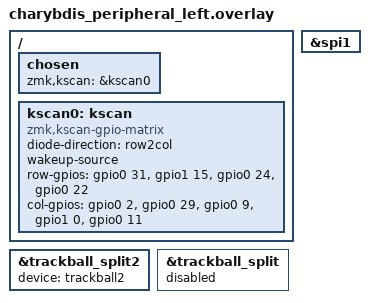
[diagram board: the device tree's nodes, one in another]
/*
 * Copyright (c) 2020 ZMK Contributors
 *
 * SPDX-License-Identifier: MIT
 */

#include "charybdis.dtsi"
#include "trackball.dtsi"
#include "split_input_common.dtsi"


/ {
    chosen {
        zmk,kscan = &kscan0;
    };
    
    kscan0: kscan {
        compatible = "zmk,kscan-gpio-matrix";
        diode-direction = "row2col";
        wakeup-source;

	row-gpios
        = <&gpio0 31 GPIO_ACTIVE_HIGH>
        , <&gpio1 15 GPIO_ACTIVE_HIGH>
        , <&gpio0 24 GPIO_ACTIVE_HIGH>
	    , <&gpio0 22 GPIO_ACTIVE_HIGH>
        ;
	col-gpios
		= <&gpio0 2 (GPIO_ACTIVE_HIGH | GPIO_PULL_DOWN)>
		, <&gpio0 29 (GPIO_ACTIVE_HIGH | GPIO_PULL_DOWN)>
		, <&gpio0 9 (GPIO_ACTIVE_HIGH | GPIO_PULL_DOWN)>
		, <&gpio1 0  (GPIO_ACTIVE_HIGH | GPIO_PULL_DOWN)>
		, <&gpio0 11 (GPIO_ACTIVE_HIGH | GPIO_PULL_DOWN)>
		;
	};
};

&spi1 {
    status = "okay";
};
&trackball_split2 {
	device = <&trackball2>;
};
&trackball_split { 
	status = "disabled"; 
};
